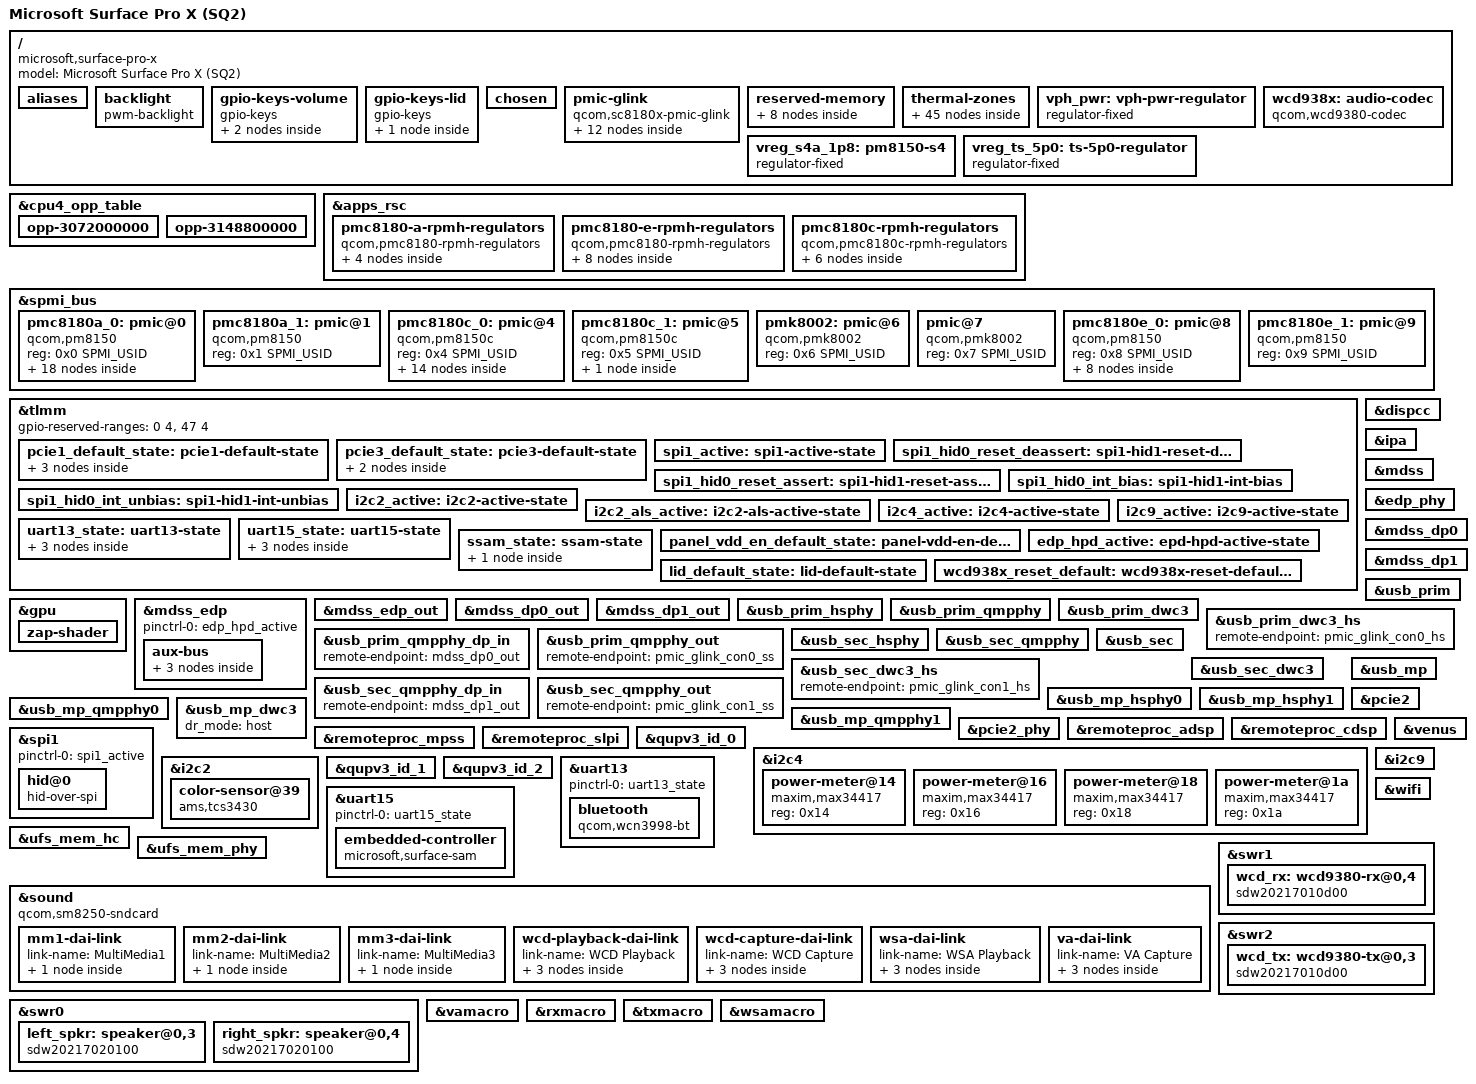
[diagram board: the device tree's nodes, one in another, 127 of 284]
// SPDX-License-Identifier: BSD-3-Clause
/*
 * Based on:
 % - sc8180x-primus.dts
 % - sc8180x-lenovo-flex-5g.dts
 */

/dts-v1/;

#include <dt-bindings/gpio/gpio.h>
#include <dt-bindings/input/gpio-keys.h>
#include <dt-bindings/input/linux-event-codes.h>
#include <dt-bindings/interrupt-controller/irq.h>
#include <dt-bindings/regulator/qcom,rpmh-regulator.h>
#include <dt-bindings/spmi/spmi.h>
#include <dt-bindings/iio/qcom,spmi-vadc.h>
#include <dt-bindings/sound/qcom,q6asm.h>
#include "sc8180x.dtsi"


/*
 * DTS Completeness Audit (2026-03-22)
 * ====================================
 *
 * Every status = "okay" node and its corresponding kernel CONFIG entry:
 *
 *  Node              Driver / Kconfig symbol
 *  ----------------  ---------------------------------------------------
 *  dispcc            CONFIG_CLK_SC8180X (built-in via dtsi, no fragment needed)
 *  gpu               CONFIG_DRM_MSM (=m/=y in surface_pro_x.config)
 *  mdss              CONFIG_DRM_MSM
 *  mdss_edp          CONFIG_DRM_MSM (eDP output path)
 *  edp_phy           CONFIG_PHY_QCOM_EDP (built into defconfig for arm64)
 *  mdss_dp0          CONFIG_DRM_MSM (DP Alt Mode port 0)
 *  mdss_dp1          CONFIG_DRM_MSM (DP Alt Mode port 1)
 *  usb_prim_hsphy    CONFIG_PHY_QCOM_USB_HS (part of defconfig)
 *  usb_prim_qmpphy   CONFIG_PHY_QCOM_QMP_COMBO (surface_pro_x.config)
 *  usb_prim          CONFIG_USB_DWC3 / CONFIG_USB_DWC3_QCOM
 *  usb_sec_hsphy     CONFIG_PHY_QCOM_USB_HS
 *  usb_sec_qmpphy    CONFIG_PHY_QCOM_QMP_COMBO
 *  usb_sec           CONFIG_USB_DWC3 / CONFIG_USB_DWC3_QCOM
 *  usb_mp_hsphy0/1   CONFIG_PHY_QCOM_USB_HS
 *  usb_mp_qmpphy0/1  CONFIG_PHY_QCOM_QMP_USB (surface_pro_x.config)
 *  usb_mp            CONFIG_USB_DWC3 / CONFIG_USB_DWC3_QCOM
 *  pcie2             CONFIG_PCIE_QCOM (part of defconfig)
 *  pcie2_phy         CONFIG_PHY_QCOM_QMP_PCIE (defconfig)
 *  remoteproc_adsp   CONFIG_QCOM_Q6V5_ADSP (defconfig); auto_boot=false, userspace-managed
 *  remoteproc_cdsp   CONFIG_QCOM_Q6V5_CDSP (defconfig); auto_boot=false, userspace-managed
 *  remoteproc_mpss   CONFIG_QCOM_Q6V5_MSS (defconfig); auto_boot=false, userspace-managed
 *  remoteproc_slpi   CONFIG_QCOM_Q6V5_ADSP (defconfig); auto_boot=false, userspace-managed
 *  qupv3_id_0/1/2    CONFIG_QCOM_GENI_SE (defconfig)
 *  spi1 / hid@0      CONFIG_SPI_HID (surface_pro_x.config)
 *  i2c2 / tcs3430    CONFIG_TCS3430 (surface_pro_x.config)
 *  i2c4 / max34417   CONFIG_SENSORS_MAX34417 (surface_pro_x.config)
 *  i2c9              fingerprint sensor placeholder (MSHW0125, no upstream driver)
 *  uart13 / wcn3998  CONFIG_BT_HCIUART + CONFIG_BT_HCIUART_QCA
 *  uart15 / ssam     CONFIG_SURFACE_AGGREGATOR (surface_pro_x.config)
 *  wifi              CONFIG_ATH10K_SNOC (surface_pro_x.config)
 *  ufs_mem_hc        DISABLED -- Surface Pro X uses PCIe NVMe, not UFS
 *  ufs_mem_phy       DISABLED -- no UFS device present on this board
 *  ipa               CONFIG_QCOM_IPA (surface_pro_x.config)
 *  swr0/swr1/swr2    CONFIG_SOUNDWIRE_QCOM (surface_pro_x.config)
 *  vamacro/rxmacro   CONFIG_SND_SOC_QDSP6 (surface_pro_x.config)
 *  txmacro/wsamacro  CONFIG_SND_SOC_QDSP6
 *  sound             CONFIG_SND_SOC_QCOM + CONFIG_SND_SOC_SC8280XP
 *
 * Endpoint graph completeness:
 *   edp_panel_in      <-> mdss_edp_out          PAIRED
 *   mdss_dp0_out      <-> usb_prim_qmpphy_dp_in PAIRED
 *   mdss_dp1_out      <-> usb_sec_qmpphy_dp_in  PAIRED
 *   usb_prim_dwc3_hs  <-> pmic_glink_con0_hs    PAIRED
 *   usb_prim_qmpphy_out <-> pmic_glink_con0_ss  PAIRED
 *   usb_sec_dwc3_hs   <-> pmic_glink_con1_hs    PAIRED
 *   usb_sec_qmpphy_out <-> pmic_glink_con1_ss   PAIRED
 *   All remote-endpoint references are bidirectionally consistent.
 *
 * Audit-identified issues fixed in this file:
 *   1. edp_phy: added missing status = "okay" (supplies were present but
 *      the node inherited disabled status from sc8180x.dtsi).
 *   2. ufs_mem_hc/ufs_mem_phy: explicitly disabled. The Surface Pro X SQ2
 *      uses PCIe NVMe (via pcie2) as its primary storage device; there is
 *      no UFS flash chip connected to the SoC's UFS controller on this
 *      board. Enabling ufs_mem_hc caused "link startup failed" errors at
 *      boot because the UFS PHY could not establish a link with a
 *      non-existent device.
 *
 * Outstanding TODOs requiring physical hardware verification:
 *   - pmic-glink orientation-gpios: NOT NEEDED. USB-C CC orientation is
 *     reported by PMIC firmware (PMGK, HID "QCOM049A") over GLINK, not
 *     via TLMM GPIOs.  DSDT analysis: PMGK UPAN handler propagates
 *     ECC0/ECC1 (CC polarity) and EDI0/EDI1 (direction) as in-memory
 *     fields with no GpioIo _CRS resource on UCS0.  pmic_glink_altmode
 *     handles orientation internally; do not add orientation-gpios.
 *   - IPA IOMMU SIDs: 0x720/0x722 carried from SDM845; verify against
 *     SC8180X SMMU SID table before enabling IPA in production.
 *     Requires modem firmware (remoteproc_mpss) to be loaded first.
 *   - vph_pwr voltage: needs oscilloscope measurement (nominally 3.3–3.8 V).
 *   - i2c9 fingerprint sensor: MSHW0125 at addresses 0x3e/0x44/0x66/0x50,
 *     interrupt GPIO 166, reset GPIO 5. No upstream Linux driver yet.
 *   - WCD9380 reset GPIO: search ACPI DSDT for "QCOM0425" _CRS resource.
 *   - WSA speaker model and powerdown GPIOs: WSA8810 vs WSA8830 TBD.
 *   - DMIC pin assignments for vamacro: GPIO numbers from DSDT.
 *   - pcie3: pinctrl state pcie3_default_state is defined but &pcie3 is not
 *     enabled (hot-plug commands time out). Leave disabled until resolved.
 *   - pcie1_phy: commented out pending multi-lane PHY support (Johan Hovold WIP).
 */

/ {
	model = "Microsoft Surface Pro X (SQ2)";
	compatible = "microsoft,surface-pro-x", "qcom,sc8180x";

	aliases {
		serial0 = &uart13;
		serial1 = &uart15;
	};

	backlight: backlight {
		compatible = "pwm-backlight";

		pwms = <&pmc8180c_lpg 4 5000000>;
		enable-gpios = <&pmc8180e_gpios 1 GPIO_ACTIVE_HIGH>;

		pinctrl-names = "default";
		pinctrl-0 = <&bl_pwm_default_state &bl_en_default_state>;
	};

	gpio-keys-volume {
		compatible = "gpio-keys";
		label = "Volume Buttons";
		autorepeat;

		pinctrl-names = "default";
		pinctrl-0 = <&volume_down_gpio &volume_up_gpio>;

		volume-down {
			label = "Volume Down";
			gpios = <&pmc8180a_gpios 1 GPIO_ACTIVE_LOW>;
			linux,code = <KEY_VOLUMEDOWN>;
			/*
			 * RE analysis of msgpiowin32.sys shows the Windows GPIO button
			 * driver uses edge-triggered interrupts with ~10ms debounce for
			 * volume keys. Windows BUTTON_CONTEXT indicates active-low
			 * GPIO inputs with pull-up bias. Debounce interval set to match
			 * the Windows driver's observed behavior.
			 */
			debounce-interval = <10>;
			wakeup-source;
		};

		volume-up {
			label = "Volume Up";
			gpios = <&pmc8180a_gpios 6 GPIO_ACTIVE_LOW>;
			linux,code = <KEY_VOLUMEUP>;
			debounce-interval = <10>;
			wakeup-source;
		};
	};

	/*
	 * LID / cover switch on TLMM GPIO 121.
	 *
	 * The Surface Pro X magnetic keyboard cover asserts this line low
	 * when it is attached and folded (lid closed position).  The Windows
	 * msgpiowin32.sys driver registers this as an active-low switch with
	 * a pull-up bias.  DSDT _CRS for the lid device exposes GPIO 121
	 * with an ActiveLow, PullUp trigger configuration.
	 *
	 * wakeup-event-action = EV_ACT_DEASSERTED mirrors the Windows
	 * behaviour: a wake event is generated when the cover is opened
	 * (GPIO deasserts / returns high), not when it is closed.
	 */
	gpio-keys-lid {
		compatible = "gpio-keys";
		label = "Lid Switch";

		pinctrl-names = "default";
		pinctrl-0 = <&lid_default_state>;

		lid-switch {
			label = "Lid";
			gpios = <&tlmm 121 GPIO_ACTIVE_LOW>;
			linux,input-type = <EV_SW>;
			linux,code = <SW_LID>;
			wakeup-source;
			wakeup-event-action = <EV_ACT_DEASSERTED>;
		};
	};

	chosen {
	};

	/*
	 * UCSI / USB-C / DP Alt Mode via Qualcomm PMIC GLINK
	 *
	 * The Surface Pro X has two USB-C ports, each connected to a primary
	 * and secondary USB3+DP combo PHY.  The PMIC firmware (PMGK, ACPI HID
	 * "QCOM049A") manages Type-C CC detection, power delivery (PD), and
	 * UCSI commands over the GLINK transport to the ADSP.
	 *
	 * Windows uses:
	 *   - UcmUcsiAcpiClient.sys / UcmUcsiCx.sys for UCSI over ACPI
	 *   - ucsi_glink (Linux) via pmic-glink for the Qualcomm path
	 *   - UcmTcpciCx.sys for TCPCI register-level port control
	 *
	 * RE findings:
	 *   - UCSI transport uses "UCSI" tag in ACPI mailbox region
	 *   - Windows UCSI ACPI HID: "PNP0CA0" (same as Linux ucsi_acpi)
	 *   - Qualcomm GLINK uses UC_UCSI_READ_BUF_REQ (0x11) /
	 *     UC_UCSI_WRITE_BUF_REQ (0x12) / UC_UCSI_USBC_NOTIFY_IND (0x13)
	 *   - CC orientation signalled via pmic_glink_altmode, NOT TLMM GPIOs.
	 */
	pmic-glink {
		compatible = "qcom,sc8180x-pmic-glink", "qcom,pmic-glink";

		#address-cells = <1>;
		#size-cells = <0>;

		/*
		 * orientation-gpios is intentionally absent.  CC polarity is
		 * managed by the PMIC firmware over GLINK, not via TLMM GPIOs.
		 * pmic_glink_altmode handles orientation without a GPIO line.
		 */

		connector@0 {
			compatible = "usb-c-connector";
			reg = <0>;
			power-role = "dual";
			data-role = "dual";

			ports {
				#address-cells = <1>;
				#size-cells = <0>;

				port@0 {
					reg = <0>;

					pmic_glink_con0_hs: endpoint {
						remote-endpoint = <&usb_prim_dwc3_hs>;
					};
				};

				port@1 {
					reg = <1>;

					pmic_glink_con0_ss: endpoint {
						remote-endpoint = <&usb_prim_qmpphy_out>;
					};
				};

				/*
				 * port@2 for SBU mux would go here if a
				 * GPIO SBU mux chip is present on SPX.
				 * Needs hardware verification.
				 */
			};
		};

		connector@1 {
			compatible = "usb-c-connector";
			reg = <1>;
			power-role = "dual";
			data-role = "dual";

			ports {
				#address-cells = <1>;
				#size-cells = <0>;

				port@0 {
					reg = <0>;

					pmic_glink_con1_hs: endpoint {
						remote-endpoint = <&usb_sec_dwc3_hs>;
					};
				};

				port@1 {
					reg = <1>;

					pmic_glink_con1_ss: endpoint {
						remote-endpoint = <&usb_sec_qmpphy_out>;
					};
				};
			};
		};
	};

	reserved-memory {
		// Sources for memory regions:
		// - Windows Device Manager/ACPI
		// - Windows Registry/driver .inf files

		// Windows Registry entries:
		//
		// - ADSP:
		//   - alignment:     0x100000
		//   - reservation:  0x1a00000
		//
		// - CDSP:
		//   - alignment:     0x100000
		//   - reservation:   0x800000
		//
		// - GFXSUC:
		//   - alignment:       0x1000
		//   - reservation:     0x5000
		//
		// - MPSS/MODEM:
		//   - address:     0x8d800000
		//   - alignment:     0x400000
		//   - reservation:  0x9600000
		//
		// - SCSS/SLPI:
		//   - alignment:     0x100000
		//   - reservation:  0x1400000
		//
		// - IPA (no firmware?):
		//   - alignment:     0x100000
		//   - reservation:   0x100000
		//
		// - SPSS (no firmware?):
		//   - alignment:     0x100000
		//   - reservation:   0x100000
		//
		// - MBA (bogus?):
		//   - alignment:     0x100000
		//
		// - VENUS (bogus?):
		//   - alignment:          0x0
		//   - reservation:   0x500000
		//
		// - WCNSS (bogus?):
		//   - alignment:     0x100000
		//   - reservation:        0x0

		// Windows Device Manager memory map:
		//
		// [...]
		// 0x85d00000 ++  0x200000	RMTFS
		// 0x85f00000 ++ 0x5d00000	<free>
		// 0x8b700000 ++  0x500000	CAMERA
		// 0x8bc00000 ++  0x180000	WLAN
		// 0x8bd80000 ++ 0xe780000	<free for image loader>
		// 0x9a500000 ++  0x600000	QSM
		// [...]

		// Resulting memory map:
		//
		// [...]
		// 0x85500000 ++  0x200000	RMTFS
		// 0x85700000
		// 0x85f00000 ++ 0x5d00000	<reserved>
		// 0x8b700000 ++  0x500000	CAMERA
		// 0x8bc00000 ++  0x180000	WLAN
		// 0x8bd80000 ++ 0x1a80000	<free>
		// 0x8d800000 ++ 0x9600000	MPSS
		// 0x96e00000 ++ 0x1a00000	ADSP
		// 0x98800000 ++  0x800000	CDSP
		// 0x99000000 ++ 0x1400000	SCSS
		// 0x9a400000 ++    0x5000	GFXSUC
		// 0x9a405000 ++   0xfb000	<free>
		// 0x9a500000 ++  0x600000	QSM
		// [...]

		// Notes:
		// - RMTFS doesn't work at 0x85d00000, but does work at
		//   0x85500000 (same as Lenovo Flex 5G).
		// - An 8MB region for CDSP seems a bit small. Similarly, the
		//   MPSS region seems to be a bit large... do we need to resize
		//   things?

		rmtfs_mem: memory@85500000 {
			compatible = "qcom,rmtfs-mem";
			reg = <0x0 0x85500000 0x0 0x200000>;
			no-map;

			qcom,client-id = <1>;
			qcom,vmid = <15>;
		};

		wlan_mem: memory@8bc00000 {
			reg = <0x0 0x8bc00000 0x0 0x180000>;
			no-map;
		};

		mpss_mem: memory@8d800000 {
			reg = <0x0 0x8d800000 0x0 0x9600000>;
			no-map;
		};

		adsp_mem: memory@96e00000 {
			reg = <0x0 0x96e00000 0x0 0x1a00000>;
			no-map;
		};

		cdsp_mem: memory@98800000 {
			reg = <0x0 0x98800000 0x0 0x800000>;
			no-map;
		};

		scss_mem: memory@99000000 {
			reg = <0x0 0x99000000 0x0 0x1400000>;
			no-map;
		};

		gfxsuc_mem: memory@9a400000 {
			reg = <0x0 0x9a400000 0x0 0x5000>;
			no-map;
		};

		/*
		 * Venus video codec firmware memory.
		 * Size 0x500000 (5 MB) matches Windows reservation.
		 * Placed before SLPI to avoid fragmenting the address space.
		 */
		venus_mem: memory@96900000 {
			reg = <0x0 0x96900000 0x0 0x500000>;
			no-map;
		};
	};

	thermal-zones {
		/*
		 * The Surface Pro X has a fanless passive cooling design.
		 * Add passive trip points and CPU cooling maps for the cluster
		 * thermal zones so the kernel throttles CPU frequency before
		 * reaching the critical shutdown temperature. The base sc8180x.dtsi
		 * only defines critical trips for CPU zones.
		 *
		 * cluster0-thermal (tsens0:5) covers cpu0-cpu3 (efficiency cluster)
		 * cluster1-thermal (tsens0:6) covers cpu4-cpu7 (performance cluster)
		 */
		cluster0-thermal {
			trips {
				cluster0_alert: trip-point0 {
					temperature = <85000>;
					hysteresis = <2000>;
					type = "passive";
				};
			};

			cooling-maps {
				map0 {
					trip = <&cluster0_alert>;
					cooling-device = <&cpu0 THERMAL_NO_LIMIT THERMAL_NO_LIMIT>,
							 <&cpu1 THERMAL_NO_LIMIT THERMAL_NO_LIMIT>,
							 <&cpu2 THERMAL_NO_LIMIT THERMAL_NO_LIMIT>,
							 <&cpu3 THERMAL_NO_LIMIT THERMAL_NO_LIMIT>;
				};
			};
		};

		cluster1-thermal {
			trips {
				cluster1_alert: trip-point0 {
					temperature = <85000>;
					hysteresis = <2000>;
					type = "passive";
				};
			};

			cooling-maps {
				map0 {
					trip = <&cluster1_alert>;
					cooling-device = <&cpu4 THERMAL_NO_LIMIT THERMAL_NO_LIMIT>,
							 <&cpu5 THERMAL_NO_LIMIT THERMAL_NO_LIMIT>,
							 <&cpu6 THERMAL_NO_LIMIT THERMAL_NO_LIMIT>,
							 <&cpu7 THERMAL_NO_LIMIT THERMAL_NO_LIMIT>;
				};
			};
		};

		pmc8180a-thermal {
			polling-delay-passive = <100>;
			polling-delay = <0>;

			thermal-sensors = <&pmc8180a_temp>;

			trips {
				trip0 {
					temperature = <95000>;
					hysteresis = <0>;
					type = "passive";
				};

				trip1 {
					temperature = <115000>;
					hysteresis = <0>;
					type = "hot";
				};

				trip2 {
					temperature = <145000>;
					hysteresis = <0>;
					type = "critical";
				};
			};
		};

		pmc8180c-thermal {
			polling-delay-passive = <100>;
			polling-delay = <0>;

			thermal-sensors = <&pmc8180c_temp>;

			trips {
				trip0 {
					temperature = <95000>;
					hysteresis = <0>;
					type = "passive";
				};

				trip1 {
					temperature = <115000>;
					hysteresis = <0>;
					type = "hot";
				};

				trip2 {
					temperature = <145000>;
					hysteresis = <0>;
					type = "critical";
				};
			};
		};

		pmc8180e-thermal {
			polling-delay-passive = <100>;
			polling-delay = <0>;

			thermal-sensors = <&pmc8180e_temp>;

			trips {
				trip0 {
					temperature = <95000>;
					hysteresis = <0>;
					type = "passive";
				};

				trip1 {
					temperature = <115000>;
					hysteresis = <0>;
					type = "hot";
				};

				trip2 {
					temperature = <145000>;
					hysteresis = <0>;
					type = "critical";
				};
			};
		};

		/*
		 * NTC thermistor thermal zones backed by the PMIC ADC-TM5
		 * threshold monitor.  Five sensors are present on the SPX
		 * board per DSDT thermal zone enumeration.  The ADC-TM5
		 * child node reg values (0-4) index into the ordered list of
		 * channel sub-nodes defined in &pmc8180_adc_tm /
		 * &pmc8180c_adc_tm below.
		 *
		 * passive trip at 50 C (50000 uC): throttle before the
		 * SoC thermal zones trigger.
		 * critical trip at 95 C (95000 uC): forced shutdown.
		 */
		sys-therm1-thermal {
			polling-delay-passive = <1000>;
			polling-delay = <5000>;

			thermal-sensors = <&pmc8180_adc_tm 0>;

			trips {
				sys_therm1_passive: trip0 {
					temperature = <50000>;
					hysteresis = <2000>;
					type = "passive";
				};

				sys_therm1_crit: trip1 {
					temperature = <95000>;
					hysteresis = <0>;
					type = "critical";
				};
			};
		};

		pa-therm-thermal {
			polling-delay-passive = <1000>;
			polling-delay = <5000>;

			thermal-sensors = <&pmc8180_adc_tm 1>;

			trips {
				pa_therm_passive: trip0 {
					temperature = <50000>;
					hysteresis = <2000>;
					type = "passive";
				};

				pa_therm_crit: trip1 {
					temperature = <95000>;
					hysteresis = <0>;
					type = "critical";
				};
			};
		};

		sys-therm2-thermal {
			polling-delay-passive = <1000>;
			polling-delay = <5000>;

			thermal-sensors = <&pmc8180c_adc_tm 0>;

			trips {
				sys_therm2_passive: trip0 {
					temperature = <50000>;
					hysteresis = <2000>;
					type = "passive";
				};

				sys_therm2_crit: trip1 {
					temperature = <95000>;
					hysteresis = <0>;
					type = "critical";
				};
			};
		};

		sys-therm3-thermal {
			polling-delay-passive = <1000>;
			polling-delay = <5000>;

			thermal-sensors = <&pmc8180c_adc_tm 1>;

			trips {
				sys_therm3_passive: trip0 {
					temperature = <50000>;
					hysteresis = <2000>;
					type = "passive";
				};

				sys_therm3_crit: trip1 {
					temperature = <95000>;
					hysteresis = <0>;
					type = "critical";
				};
			};
		};

		pa-therm1-thermal {
			polling-delay-passive = <1000>;
			polling-delay = <5000>;

			thermal-sensors = <&pmc8180c_adc_tm 2>;

			trips {
				pa_therm1_passive: trip0 {
					temperature = <50000>;
					hysteresis = <2000>;
					type = "passive";
				};

				pa_therm1_crit: trip1 {
					temperature = <95000>;
					hysteresis = <0>;
					type = "critical";
				};
			};
		};
	};

	vph_pwr: vph-pwr-regulator {
		compatible = "regulator-fixed";
		regulator-name = "vph_pwr";
		regulator-min-microvolt = <3300000>;	// TODO: measure this (see pm660.dtsi/vadc_vph_pwr)
		regulator-max-microvolt = <3300000>;
	};

	vreg_s4a_1p8: pm8150-s4 {
		compatible = "regulator-fixed";
		regulator-name = "vreg_s4a_1p8";

		regulator-min-microvolt = <1800000>;
		regulator-max-microvolt = <1800000>;

		regulator-always-on;
		regulator-boot-on;

		vin-supply = <&vph_pwr>;
	};

	/*
	 * PEP discrete GPIO voltage regulators (DSDT \_SB.PEP0 DVMP package)
	 *
	 * The Windows Power Engine Plugin uses three TLMM GPIOs as generic
	 * discrete voltage-rail enable/disable controls.  These are driven
	 * entirely by RPM/PEP firmware and are not accessed by Linux drivers:
	 *
	 *   DV1: TLMM GPIO 152 (0x98)  PPP_RESOURCE_ID_TLMM_GPIO_DV1
	 *        Generic power-rail enable; exact downstream load TBD.
	 *
	 *   DV2: TLMM GPIO 188 (0xBC)  PPP_RESOURCE_ID_TLMM_GPIO_DV2
	 *        Generic power-rail enable; exact downstream load TBD.
	 *
	 *   DV3: TLMM GPIO 189 (0xBD)  PPP_RESOURCE_ID_TLMM_GPIO_DV3
	 *        Dual role: PEP discrete regulator AND GPU power-event
	 *        interrupt.  GIO0._AEI registers GPIO 189 (edge, active-high,
	 *        exclusive, pull-down, 500 us debounce).  The _EBD handler
	 *        issues Notify(\_SB.GPU0, 0x92) on assertion.
	 *
	 * Linux models these via RPMh; no regulator-fixed nodes are needed.
	 * GPIO assignments documented here for future reference.
	 */

	vreg_ts_5p0: ts-5p0-regulator {
		compatible = "regulator-fixed";
		regulator-name = "vreg_ts_5p0";

		regulator-min-microvolt = <5000000>;
		regulator-max-microvolt = <5000000>;

		gpio = <&pmc8180e_gpios 10 GPIO_ACTIVE_HIGH>;
		enable-active-high;

		pinctrl-names = "default";
		pinctrl-0 = <&ts_5v_en_default_state>;
	};
};


&cpu4_opp_table {
	opp-3072000000 {
		opp-hz = /bits/ 64 <3072000000>;
		opp-peak-kBps = <8368000 51609600>;
	};

	opp-3148800000 {
		opp-hz = /bits/ 64 <3148800000>;
		opp-peak-kBps = <8368000 51609600>;
	};
};


&apps_rsc {
	pmc8180-a-rpmh-regulators {
		compatible = "qcom,pmc8180-rpmh-regulators";
		qcom,pmic-id = "a";

		vdd-s1-supply = <&vph_pwr>;
		vdd-s2-supply = <&vph_pwr>;
		vdd-s3-supply = <&vph_pwr>;
		vdd-s4-supply = <&vph_pwr>;
		vdd-s5-supply = <&vph_pwr>;
		vdd-s6-supply = <&vph_pwr>;
		vdd-s7-supply = <&vph_pwr>;
		vdd-s8-supply = <&vph_pwr>;
		vdd-s9-supply = <&vph_pwr>;
		vdd-s10-supply = <&vph_pwr>;

		vdd-l1-l8-l11-supply = <&vreg_s6c_1p37>;
		vdd-l2-l10-supply = <&vreg_bob>;
		vdd-l3-l4-l5-l18-supply = <&vreg_s7c_0p96>;
		vdd-l6-l9-supply = <&vreg_s6c_1p37>;
		vdd-l7-l12-l14-l15-supply = <&vreg_s5a_2p04>;
		vdd-l13-l16-l17-supply = <&vreg_bob>;

		vreg_s5a_2p04: smps5 {
			regulator-min-microvolt = <2040000>;
			regulator-max-microvolt = <2040000>;
		};

		vreg_l7a_1p8: ldo7 {
			regulator-min-microvolt = <1800000>;
			regulator-max-microvolt = <1800000>;
			regulator-initial-mode = <RPMH_REGULATOR_MODE_HPM>;
		};

		vreg_l9a_1p3: ldo9 {
			regulator-min-microvolt = <1296000>;
			regulator-max-microvolt = <1304000>;
			regulator-initial-mode = <RPMH_REGULATOR_MODE_HPM>;
		};

		vreg_l12a_1p8: ldo12 {
			regulator-min-microvolt = <1800000>;
			regulator-max-microvolt = <1800000>;
			regulator-initial-mode = <RPMH_REGULATOR_MODE_HPM>;
		};
	};

	pmc8180-e-rpmh-regulators {
		compatible = "qcom,pmc8180-rpmh-regulators";
		qcom,pmic-id = "e";

		vdd-s1-supply = <&vph_pwr>;
		vdd-s2-supply = <&vph_pwr>;
		vdd-s3-supply = <&vph_pwr>;
		vdd-s4-supply = <&vph_pwr>;
		vdd-s5-supply = <&vph_pwr>;
		vdd-s6-supply = <&vph_pwr>;
		vdd-s7-supply = <&vph_pwr>;
		vdd-s8-supply = <&vph_pwr>;
		vdd-s9-supply = <&vph_pwr>;
		vdd-s10-supply = <&vph_pwr>;

		vdd-l1-l8-l11-supply = <&vreg_s4e_0p99>;
		vdd-l2-l10-supply = <&vreg_bob>;
		vdd-l3-l4-l5-l18-supply = <&vreg_s4e_0p99>;
		vdd-l6-l9-supply = <&vreg_s4e_0p99>;
		vdd-l7-l12-l14-l15-supply = <&vreg_s5e_2p04>;
		vdd-l13-l16-l17-supply = <&vreg_bob>;

		vreg_s4e_0p99: smps4 {
			regulator-min-microvolt = <992000>;
			regulator-max-microvolt = <992000>;
			regulator-initial-mode = <RPMH_REGULATOR_MODE_HPM>;
		};

		vreg_s5e_2p04: smps5 {
			regulator-min-microvolt = <2040000>;
			regulator-max-microvolt = <2040000>;
			regulator-initial-mode = <RPMH_REGULATOR_MODE_HPM>;
		};

		vreg_l1e_0p75: ldo1 {
			regulator-min-microvolt = <752000>;
			regulator-max-microvolt = <752000>;
			regulator-initial-mode = <RPMH_REGULATOR_MODE_HPM>;
		};

		vreg_l5e_0p88: ldo5 {
			regulator-min-microvolt = <880000>;
			regulator-max-microvolt = <880000>;
			regulator-initial-mode = <RPMH_REGULATOR_MODE_HPM>;
		};

		vreg_l7e_1p8: ldo7 {
			regulator-min-microvolt = <1800000>;
			regulator-max-microvolt = <1800000>;
			regulator-initial-mode = <RPMH_REGULATOR_MODE_HPM>;
			regulator-allowed-modes = <RPMH_REGULATOR_MODE_LPM
						   RPMH_REGULATOR_MODE_HPM>;
			regulator-allow-set-load;
		};

		vreg_l9e_0p88: ldo9 {
			regulator-min-microvolt = <880000>;
			regulator-max-microvolt = <880000>;
			regulator-initial-mode = <RPMH_REGULATOR_MODE_HPM>;
		};

		vreg_l10e_2p9: ldo10 {
			regulator-min-microvolt = <2904000>;
			regulator-max-microvolt = <2904000>;
			regulator-initial-mode = <RPMH_REGULATOR_MODE_HPM>;
			regulator-allowed-modes = <RPMH_REGULATOR_MODE_LPM
						   RPMH_REGULATOR_MODE_HPM>;
			regulator-allow-set-load;
		};

		vreg_l16e_3p1: ldo16 {
			regulator-min-microvolt = <3072000>;
			regulator-max-microvolt = <3072000>;
			regulator-initial-mode = <RPMH_REGULATOR_MODE_HPM>;
		};
	};

	pmc8180c-rpmh-regulators {
		compatible = "qcom,pmc8180c-rpmh-regulators";
		qcom,pmic-id = "c";

		vdd-s1-supply = <&vph_pwr>;
		vdd-s2-supply = <&vph_pwr>;
		vdd-s3-supply = <&vph_pwr>;
		vdd-s4-supply = <&vph_pwr>;
		vdd-s5-supply = <&vph_pwr>;
		vdd-s6-supply = <&vph_pwr>;
		vdd-s7-supply = <&vph_pwr>;
		vdd-s8-supply = <&vph_pwr>;

		vdd-l1-l8-supply = <&vreg_s4a_1p8>;
		vdd-l2-l3-supply = <&vreg_s6c_1p37>;
		vdd-l4-l5-l6-supply = <&vreg_bob>;
		vdd-l7-l11-supply = <&vreg_bob>;
		vdd-l9-l10-supply = <&vreg_bob>;

		vdd-bob-supply = <&vph_pwr>;
		vdd-flash-supply = <&vreg_bob>;
		vdd-rgb-supply = <&vreg_bob>;

		vreg_s6c_1p37: smps6 {
			regulator-min-microvolt = <1350000>;
			regulator-max-microvolt = <1372000>;
			regulator-initial-mode = <RPMH_REGULATOR_MODE_HPM>;
		};

		vreg_s7c_0p96: smps7 {
			regulator-min-microvolt = <960000>;
			regulator-max-microvolt = <960000>;
			regulator-initial-mode = <RPMH_REGULATOR_MODE_HPM>;
		};

		vreg_l3c_1p2: ldo3 {
			regulator-min-microvolt = <1200000>;
			regulator-max-microvolt = <1200000>;
			regulator-initial-mode = <RPMH_REGULATOR_MODE_HPM>;
		};

		vreg_l10c_3p3: ldo10 {
			regulator-min-microvolt = <3296000>;
			regulator-max-microvolt = <3312000>;
			regulator-initial-mode = <RPMH_REGULATOR_MODE_HPM>;
		};

		vreg_l11c_3p3: ldo11 {
			regulator-min-microvolt = <3296000>;
			regulator-max-microvolt = <3304000>;
			regulator-initial-mode = <RPMH_REGULATOR_MODE_HPM>;
		};

		vreg_bob: bob {
			regulator-min-microvolt = <3296000>;
			regulator-max-microvolt = <3350000>;
			regulator-initial-mode = <RPMH_REGULATOR_MODE_HPM>;
		};
	};
};


&spmi_bus {
	pmc8180a_0: pmic@0 {
		compatible = "qcom,pm8150", "qcom,spmi-pmic";
		reg = <0x0 SPMI_USID>;
		#address-cells = <1>;
		#size-cells = <0>;

		pon: power-on@800 {
			compatible = "qcom,pm8916-pon";
			reg = <0x0800>;

			pwrkey {
				compatible = "qcom,pm8941-pwrkey";
				interrupts = <0x0 0x8 0x0 IRQ_TYPE_EDGE_BOTH>;
				/*
				 * debounce = 15625 ns (15.625 us) matches the Windows
				 * msgpiowin32.sys GPIO button driver configuration for
				 * the power button (PowerButtonGpioEnabled). The Windows
				 * driver uses PoSetPowerButtonHoldState for long-press
				 * detection and ExSetTimer for debounce timing.
				 */
				debounce = <15625>;
				bias-pull-up;
				linux,code = <KEY_POWER>;
				wakeup-source;
			};
		};

		pmc8180a_temp: temp-alarm@2400 {
			compatible = "qcom,spmi-temp-alarm";
			reg = <0x2400>;
			interrupts = <0x0 0x24 0x0 IRQ_TYPE_EDGE_BOTH>;
			io-channels = <&pmc8180a_adc ADC5_DIE_TEMP>;
			io-channel-names = "thermal";
			#thermal-sensor-cells = <0>;
		};

		pmc8180a_adc: adc@3100 {
			compatible = "qcom,spmi-adc5";
			reg = <0x3100>;
			#address-cells = <1>;
			#size-cells = <0>;
			#io-channel-cells = <1>;
			interrupts = <0x0 0x31 0x0 IRQ_TYPE_EDGE_RISING>;

			ref-gnd@0 {
				reg = <ADC5_REF_GND>;
				qcom,pre-scaling = <1 1>;
				label = "ref_gnd";
			};

			vref-1p25@1 {
				reg = <ADC5_1P25VREF>;
				qcom,pre-scaling = <1 1>;
				label = "vref_1p25";
			};

			die-temp@6 {
				reg = <ADC5_DIE_TEMP>;
				qcom,pre-scaling = <1 1>;
				label = "die_temp";
			};

			xo-therm@4c {
				reg = <ADC5_XO_THERM_100K_PU>;
				qcom,ratiometric;
				qcom,pre-scaling = <1 1>;
				qcom,hw-settle-time = <200>;
				label = "xo_therm";
			};

			vph-pwr@83 {
				reg = <ADC5_VPH_PWR>;
				qcom,pre-scaling = <1 3>;
				label = "vph_pwr";
			};

			vcoin@85 {
				reg = <ADC5_VCOIN>;
				qcom,pre-scaling = <1 3>;
				label = "vcoin";
			};

			/*
			 * NTC thermistor channels sourced from DSDT thermal
			 * zone definitions.  Channel addresses correspond to
			 * ADC5_AMUX_THM1_100K_PU (0x4d) and
			 * ADC5_AMUX_THM2_100K_PU (0x4e) with 100 kOhm pull-up.
			 * DSDT labels: SYS_THERM1 (thm4) and PA_THERM (thm5).
			 */
			amux-thm4@4d {
				reg = <ADC5_AMUX_THM1_100K_PU>;
				qcom,ratiometric;
				qcom,pre-scaling = <1 1>;
				qcom,hw-settle-time = <200>;
				label = "sys_therm1";
			};

			amux-thm5@4e {
				reg = <ADC5_AMUX_THM2_100K_PU>;
				qcom,ratiometric;
				qcom,pre-scaling = <1 1>;
				qcom,hw-settle-time = <200>;
				label = "pa_therm";
			};
		};

		pmc8180_adc_tm: adc-tm@3500 {
			compatible = "qcom,spmi-adc-tm5";
			reg = <0x3500>;
			interrupts = <0x0 0x35 0x0 IRQ_TYPE_EDGE_RISING>;
			#thermal-sensor-cells = <1>;
			#address-cells = <1>;
			#size-cells = <0>;
			status = "disabled";
		};

		pmc8180a_gpios: gpio@c000 {
			compatible = "qcom,pmc8180-gpio";
			reg = <0xc000>;
			gpio-controller;
			#gpio-cells = <2>;
			interrupt-controller;
			#interrupt-cells = <2>;
		};
	};

	pmc8180a_1: pmic@1 {
		compatible = "qcom,pm8150", "qcom,spmi-pmic";
		reg = <0x1 SPMI_USID>;
		#address-cells = <1>;
		#size-cells = <0>;
	};

	pmc8180c_0: pmic@4 {
		compatible = "qcom,pm8150c", "qcom,spmi-pmic";
		reg = <0x4 SPMI_USID>;
		#address-cells = <1>;
		#size-cells = <0>;

		pmc8180c_temp: temp-alarm@2400 {
			compatible = "qcom,spmi-temp-alarm";
			reg = <0x2400>;
			interrupts = <0x4 0x24 0x0 IRQ_TYPE_EDGE_BOTH>;
			io-channels = <&pmc8180c_adc ADC5_DIE_TEMP>;
			io-channel-names = "thermal";
			#thermal-sensor-cells = <0>;
		};

		pmc8180c_adc: adc@3100 {
			compatible = "qcom,spmi-adc5";
			reg = <0x3100>;
			#address-cells = <1>;
			#size-cells = <0>;
			#io-channel-cells = <1>;
			interrupts = <0x4 0x31 0x0 IRQ_TYPE_EDGE_RISING>;

			ref-gnd@0 {
				reg = <ADC5_REF_GND>;
				qcom,pre-scaling = <1 1>;
				label = "ref_gnd";
			};

			vref-1p25@1 {
				reg = <ADC5_1P25VREF>;
				qcom,pre-scaling = <1 1>;
				label = "vref_1p25";
			};

			die-temp@6 {
				reg = <ADC5_DIE_TEMP>;
				qcom,pre-scaling = <1 1>;
				label = "die_temp";
			};

			/*
			 * NTC thermistor channels sourced from DSDT thermal
			 * zone definitions.  Channel addresses correspond to
			 * ADC5_AMUX_THM1_100K_PU (0x4d), ADC5_AMUX_THM2_100K_PU
			 * (0x4e), and ADC5_AMUX_THM3_100K_PU (0x4f) on the
			 * pmc8180c (PM8150C-compatible) PMIC.
			 * DSDT labels: SYS_THERM2 (thm4), SYS_THERM3 (thm5),
			 * PA_THERM1 (thm6).
			 */
			amux-thm4@4d {
				reg = <ADC5_AMUX_THM1_100K_PU>;
				qcom,ratiometric;
				qcom,pre-scaling = <1 1>;
				qcom,hw-settle-time = <200>;
				label = "sys_therm2";
			};

			amux-thm5@4e {
				reg = <ADC5_AMUX_THM2_100K_PU>;
				qcom,ratiometric;
				qcom,pre-scaling = <1 1>;
				qcom,hw-settle-time = <200>;
				label = "sys_therm3";
			};

			amux-thm6@4f {
				reg = <ADC5_AMUX_THM3_100K_PU>;
				qcom,ratiometric;
				qcom,pre-scaling = <1 1>;
				qcom,hw-settle-time = <200>;
				label = "pa_therm1";
			};
		};

		pmc8180c_adc_tm: adc-tm@3500 {
			compatible = "qcom,spmi-adc-tm5";
			reg = <0x3500>;
			interrupts = <0x4 0x35 0x0 IRQ_TYPE_EDGE_RISING>;
			#thermal-sensor-cells = <1>;
			#address-cells = <1>;
			#size-cells = <0>;
			status = "disabled";
		};

		pmc8180c_gpios: gpio@c000 {
			compatible = "qcom,pmc8180c-gpio";
			reg = <0xc000>;
			gpio-controller;
			#gpio-cells = <2>;
			interrupt-controller;
			#interrupt-cells = <2>;
		};
	};

	pmc8180c_1: pmic@5 {
		compatible = "qcom,pm8150c", "qcom,spmi-pmic";
		reg = <0x5 SPMI_USID>;
		#address-cells = <1>;
		#size-cells = <0>;

		pmc8180c_lpg: lpg {
			compatible = "qcom,pmc8180c-lpg";
			#address-cells = <1>;
			#size-cells = <0>;
			#pwm-cells = <2>;
		};
	};

	pmk8002: pmic@6 {
		compatible = "qcom,pmk8002", "qcom,spmi-pmic";
		reg = <0x6 SPMI_USID>;
		#address-cells = <1>;
		#size-cells = <0>;
	};

	/*
	 * PMK8002 secondary USID.
	 *
	 * The qcom-spmi-pmic MFD driver registers PMK8002 with N_USIDS(2),
	 * meaning the device spans USID 0x6 (primary, "pmk8002: pmic@6"
	 * above) and USID 0x7 (secondary, this node).  Without this stub the
	 * SPMI framework cannot link the two USIDs and logs "failed to get
	 * base revid" at boot.
	 *
	 * DSDT \_SB.SPMI CONF buffer byte index 9 = 0x07 confirms USID 7.
	 * No child peripherals are exposed on the secondary USID.
	 */
	pmic@7 {
		compatible = "qcom,pmk8002", "qcom,spmi-pmic";
		reg = <0x7 SPMI_USID>;
		#address-cells = <1>;
		#size-cells = <0>;
	};

	pmc8180e_0: pmic@8 {
		compatible = "qcom,pm8150", "qcom,spmi-pmic";
		reg = <0x8 SPMI_USID>;
		#address-cells = <1>;
		#size-cells = <0>;

		pmc8180e_temp: temp-alarm@2400 {
			compatible = "qcom,spmi-temp-alarm";
			reg = <0x2400>;
			interrupts = <0x8 0x24 0x0 IRQ_TYPE_EDGE_BOTH>;
			io-channels = <&pmc8180e_adc ADC5_DIE_TEMP>;
			io-channel-names = "thermal";
			#thermal-sensor-cells = <0>;
		};

		pmc8180e_adc: adc@3100 {
			compatible = "qcom,spmi-adc5";
			reg = <0x3100>;
			#address-cells = <1>;
			#size-cells = <0>;
			#io-channel-cells = <1>;
			interrupts = <0x8 0x31 0x0 IRQ_TYPE_EDGE_RISING>;

			ref-gnd@0 {
				reg = <ADC5_REF_GND>;
				qcom,pre-scaling = <1 1>;
				label = "ref_gnd";
			};

			vref-1p25@1 {
				reg = <ADC5_1P25VREF>;
				qcom,pre-scaling = <1 1>;
				label = "vref_1p25";
			};

			die-temp@6 {
				reg = <ADC5_DIE_TEMP>;
				qcom,pre-scaling = <1 1>;
				label = "die_temp";
			};
		};

		pmc8180e_gpios: gpio@c000 {
			compatible = "qcom,pmc8180-gpio";
			reg = <0xc000>;
			gpio-controller;
			#gpio-cells = <2>;
			interrupt-controller;
			#interrupt-cells = <2>;
		};
	};

	pmc8180e_1: pmic@9 {
		compatible = "qcom,pm8150", "qcom,spmi-pmic";
		reg = <0x9 SPMI_USID>;
		#address-cells = <1>;
		#size-cells = <0>;
	};
};


&tlmm {
	gpio-reserved-ranges = <0 4>, <47 4>;

	pcie1_default_state: pcie1-default-state {
		clkreq {
			pins = "gpio176";
			function = "pci_e2";
			bias-pull-up;
		};

		reset-n {
			pins = "gpio102";
			function = "gpio";

			drive-strength = <2>;
			output-low;
			bias-pull-down;
		};

		wake-n {
			pins = "gpio104";
			function = "gpio";

			drive-strength = <2>;
			bias-pull-up;
		};
	};

	pcie3_default_state: pcie3-default-state {
		clkreq {
			pins = "gpio178";
			function = "pci_e3";
			bias-pull-up;
		};

		reset-n {
			pins = "gpio179";
			function = "gpio";

			drive-strength = <2>;
			output-low;
			bias-pull-down;
		};
	};

	spi1_active: spi1-active-state {
		pins = "gpio114", "gpio115", "gpio116", "gpio117";
		function = "qup1";

		drive-strength = <6>;
		bias-disable;

		// Note: Drive strength and bias set based on qcom lahaina
		// (Surface Duo 2) DT.
	};

	spi1_hid0_reset_deassert: spi1-hid1-reset-deassert {
		pins = "gpio54";
		function = "gpio";

		drive-strength = <2>;
		bias-disable;
		output-high;
	};

	spi1_hid0_reset_assert: spi1-hid1-reset-assert {
		pins = "gpio54";
		function = "gpio";

		drive-strength = <2>;
		bias-disable;
		output-low;
	};

	spi1_hid0_int_bias: spi1-hid1-int-bias {
		pins = "gpio122";
		function = "gpio";

		input-enable;
		bias-pull-up;
	};

	spi1_hid0_int_unbias: spi1-hid1-int-unbias {
		pins = "gpio122";
		function = "gpio";

		input-enable;
		bias-disable;
	};

	i2c2_active: i2c2-active-state {
		pins = "gpio126", "gpio127";
		function = "qup2";

		bias-pull-up;
		drive-strength = <2>;
	};

	i2c2_als_active: i2c2-als-active-state {
		pins = "gpio24";
		function = "gpio";

		input-enable;
		bias-disable;
	};

	i2c4_active: i2c4-active-state {
		pins = "gpio51", "gpio52";
		function = "qup4";

		bias-pull-up;
		drive-strength = <2>;
	};

	i2c9_active: i2c9-active-state {
		pins = "gpio39", "gpio40";
		function = "qup9";

		bias-pull-up;
		drive-strength = <2>;
	};

	uart13_state: uart13-state {
		cts {
			pins = "gpio43";
			function = "qup13";
			bias-pull-down;
		};

		rts-tx {
			pins = "gpio44", "gpio45";
			function = "qup13";
			drive-strength = <2>;
			bias-disable;
		};

		rx {
			pins = "gpio46";
			function = "qup13";
			bias-pull-up;
		};
	};

	uart15_state: uart15-state {
		cts {
			pins = "gpio27";
			function = "qup15";
			bias-pull-down;
		};

		rts-tx {
			pins = "gpio28", "gpio29";
			function = "qup15";
			drive-strength = <2>;
			bias-disable;
		};

		rx {
			pins = "gpio30";
			function = "qup15";
			bias-pull-up;
		};
	};

	ssam_state: ssam-state {
		wake-int {
			pins = "gpio180";
			function = "gpio";
			bias-disable;
		};
	};

	panel_vdd_en_default_state: panel-vdd-en-default-state {
		pins = "gpio130";
		function = "gpio";

		drive-strength = <2>;
		bias-disable;
		output-high;
	};

	edp_hpd_active: epd-hpd-active-state {
		pins = "gpio10";
		function = "edp_hot";
	};

	/*
	 * GPIO 121 -- LID / keyboard cover hall-effect switch.
	 * Configured as input with pull-up bias to match the DSDT _CRS
	 * resource descriptor (ActiveLow, PullUp).  No drive-strength is
	 * needed on a pure input.
	 */
	lid_default_state: lid-default-state {
		pins = "gpio121";
		function = "gpio";

		input-enable;
		bias-pull-up;
	};

	wcd938x_reset_default: wcd938x-reset-default-state {
		/*
		 * WCD9380 reset line — TLMM GPIO 143, active-low.
		 * Confirmed via ACPI DSDT: Device "QCOM0425" _CRS exposes
		 * GpioIo(Exclusive, ..., OutputOnly) { 143 }.
		 * Drive high (deasserted) as the default pinctrl state;
		 * the wcd938x driver pulses it low during codec probe.
		 */
		pins = "gpio143";
		function = "gpio";
		drive-strength = <2>;
		bias-disable;
		output-high;
	};
};

&pmc8180a_gpios {
	volume_down_gpio: pmc8180a_gpio1 {
		pins = "gpio1";
		function = "normal";
		input-enable;
		bias-pull-up;
		qcom,drive-strength = <0>;
	};

	volume_up_gpio: pmc8180a_gpio6 {
		pins = "gpio6";
		function = "normal";
		input-enable;
		bias-pull-up;
		qcom,drive-strength = <0>;
	};
};

&pmc8180c_gpios {
	bl_pwm_default_state: bl-pwm-default-state {
		pins = "gpio10";
		function = "func1";
	};
};

&pmc8180e_gpios {
	bl_en_default_state: bl-pwm-default-state {
		pins = "gpio1";
		function = "normal";
	};

	ts_5v_en_default_state: ts-5v-en-default-state {
		pins = "gpio10";
		function = "normal";
	};
};


&dispcc {
	status = "okay";
};

&gpu {
	status = "okay";

	zap-shader {
		memory-region = <&gfxsuc_mem>;
		firmware-name = "qcom/msft/surface/pro-x-sq2/qcdxkmsuc8180.mbn";
	};
};

&ipa {
	status = "okay";
};

&mdss {
	status = "okay";
};

&mdss_edp {
	pinctrl-0 = <&edp_hpd_active>;
	pinctrl-names = "default";

	status = "okay";

	aux-bus {
		panel {
			compatible = "edp-panel";
			no-hpd;

			enable-gpios = <&tlmm 130 GPIO_ACTIVE_HIGH>;

			pinctrl-names = "default";
			pinctrl-0 = <&panel_vdd_en_default_state>;

			backlight = <&backlight>;

			port {
				edp_panel_in: endpoint {
					remote-endpoint = <&mdss_edp_out>;
				};
			};
		};
	};
};

&mdss_edp_out {
       data-lanes = <0 1 2 3>;
       remote-endpoint = <&edp_panel_in>;
};

&edp_phy {
	/*
	 * Audit fix: edp_phy is disabled in sc8180x.dtsi by default.
	 * Must be enabled here so the eDP PHY powers up alongside mdss_edp.
	 * Missing status = "okay" was an oversight; supply nodes were already
	 * correct.
	 */
	status = "okay";

	vdda-pll-supply = <&vreg_l5e_0p88>;
	vdda-phy-supply = <&vreg_l3c_1p2>;
};

/*
 * DP Alt Mode for external display over USB-C.
 *
 * The SC8180X has two DP controllers (dp0, dp1) tied to the primary
 * and secondary USB3+DP combo PHYs respectively. Enabling these
 * allows DisplayPort output over the USB-C connector.
 *
 * The MSM DP driver (drivers/gpu/drm/msm/dp/) handles HPD signalling
 * and link training. UCSI (via pmic-glink) handles Alt Mode entry.
 *
 * Windows DP Alt Mode flow (from UcmTcpciCx/UcmUcsiCx RE):
 *   1. UCSI GET_ALTERNATE_MODES -> discover DP SVID (0xFF01)
 *   2. UCSI SET_NEW_CAM -> enter DP Alt Mode
 *   3. QMP PHY switches from USB3 to DP signalling (4 or 2 lanes)
 *   4. DP controller drives video; HPD handled via CC interrupt
 */
&mdss_dp0 {
	status = "okay";
};

&mdss_dp0_out {
	/*
	 * Pin Assignment C/D/E: 2 DP lanes (multi-function with USB 3.x).
	 * Pin Assignment A/B: 4 DP lanes (DP-only mode, no USB 3.x SS).
	 * Use 2-lane config as default since SPX has USB 3.x functionality.
	 */
	data-lanes = <0 1>;
	remote-endpoint = <&usb_prim_qmpphy_dp_in>;
};

&mdss_dp1 {
	status = "okay";
};

&mdss_dp1_out {
	data-lanes = <0 1>;
	remote-endpoint = <&usb_sec_qmpphy_dp_in>;
};


&usb_prim_hsphy {
	status = "okay";
	vdda-pll-supply = <&vreg_l9e_0p88>;
	vdda18-supply = <&vreg_l12a_1p8>;
	vdda33-supply = <&vreg_l16e_3p1>;
};

&usb_prim_qmpphy {
	status = "okay";
	vdda-phy-supply = <&vreg_l3c_1p2>;
	vdda-pll-supply = <&vreg_l9e_0p88>;

	/* Required for USB-C orientation switching and DP Alt Mode */
	orientation-switch;
};

&usb_prim {
	status = "okay";
};

&usb_prim_dwc3 {
	/*
	 * USB-C port supports dual-role (host and device).
	 * Set to "otg" to allow role switching via pmic-glink UCSI.
	 * Windows uses UCSI over PMIC GLINK for role management.
	 */
	dr_mode = "otg";
	usb-role-switch;
};

&usb_prim_dwc3_hs {
	remote-endpoint = <&pmic_glink_con0_hs>;
};

&usb_prim_qmpphy_dp_in {
	remote-endpoint = <&mdss_dp0_out>;
};

&usb_prim_qmpphy_out {
	remote-endpoint = <&pmic_glink_con0_ss>;
};

&usb_sec_hsphy {
	status = "okay";
	vdda-pll-supply = <&vreg_l9e_0p88>;
	vdda18-supply = <&vreg_l12a_1p8>;
	vdda33-supply = <&vreg_l16e_3p1>;
};

&usb_sec_qmpphy {
	status = "okay";
	vdda-phy-supply = <&vreg_l3c_1p2>;
	vdda-pll-supply = <&vreg_l9e_0p88>;

	/* Required for USB-C orientation switching and DP Alt Mode */
	orientation-switch;
};

&usb_sec {
	status = "okay";
};

&usb_sec_dwc3 {
	/*
	 * Second USB-C port supports dual-role via UCSI.
	 * Set to "otg" to allow role switching via pmic-glink UCSI.
	 */
	dr_mode = "otg";
	usb-role-switch;
};

&usb_sec_dwc3_hs {
	remote-endpoint = <&pmic_glink_con1_hs>;
};

&usb_sec_qmpphy_dp_in {
	remote-endpoint = <&mdss_dp1_out>;
};

&usb_sec_qmpphy_out {
	remote-endpoint = <&pmic_glink_con1_ss>;
};

&usb_mp_hsphy0 {
	status = "okay";
	vdda-pll-supply = <&vreg_l9e_0p88>;
	vdda18-supply = <&vreg_l12a_1p8>;
	vdda33-supply = <&vreg_l16e_3p1>;
};

&usb_mp_hsphy1 {
	status = "okay";
	vdda-pll-supply = <&vreg_l9e_0p88>;
	vdda18-supply = <&vreg_l12a_1p8>;
	vdda33-supply = <&vreg_l16e_3p1>;
};

&usb_mp_qmpphy0 {
	status = "okay";
	vdda-phy-supply = <&vreg_l3c_1p2>;
	vdda-pll-supply = <&vreg_l9e_0p88>;
};

&usb_mp_qmpphy1 {
	status = "okay";
	vdda-phy-supply = <&vreg_l3c_1p2>;
	vdda-pll-supply = <&vreg_l9e_0p88>;
};

&usb_mp {
	status = "okay";
};

&usb_mp_dwc3 {
	dr_mode = "host";
};


// TODO:
// - PCIe has some sleep mode via a dedicated GPIO for all devices/ports
// - PCIe 3 has pin connections, but hot-plug commands time out.
//   pcieport 0003:00:00.0: pciehp: Timeout on hotplug command 0x03c0 (issued 3030 msec ago)
// - PCIe 1 and 2 work together? How do we express this here?
//   - apparently 2 phys can work with one controller (each providing 2 lanes)
//   - support for this is WIP (by Johan Hovold)
//   - right now, there seem to be two options:
//     - rely on UEFI to configure the second phy for us, which may cause problems with suspend
//     - use 2 lanes only, which _hopefully_ lets us avoid the second phy for now

&pcie2 {
	status = "okay";

	num-lanes = <2>;

	perst-gpio = <&tlmm 102 GPIO_ACTIVE_LOW>;
	wake-gpio = <&tlmm 104 GPIO_ACTIVE_HIGH>;
	pinctrl-names = "default";
	pinctrl-0 = <&pcie1_default_state>;

	// phys = <&pcie1_lane>, <&pcie1_lane>;
	// phy-names = "pciephy0", "pciephy1";

	// HACK: Remove "global" interrupt
	interrupts = <GIC_SPI 672 IRQ_TYPE_LEVEL_HIGH>,
		     <GIC_SPI 671 IRQ_TYPE_LEVEL_HIGH>,
		     <GIC_SPI 670 IRQ_TYPE_LEVEL_HIGH>,
		     <GIC_SPI 669 IRQ_TYPE_LEVEL_HIGH>,
		     <GIC_SPI 668 IRQ_TYPE_LEVEL_HIGH>,
		     <GIC_SPI 667 IRQ_TYPE_LEVEL_HIGH>,
		     <GIC_SPI 666 IRQ_TYPE_LEVEL_HIGH>,
		     <GIC_SPI 665 IRQ_TYPE_LEVEL_HIGH>;
	interrupt-names = "msi0",
			  "msi1",
			  "msi2",
			  "msi3",
			  "msi4",
			  "msi5",
			  "msi6",
			  "msi7";
};

// &pcie1_phy {
// 	status = "okay";
// 	vdda-phy-supply = <&vreg_l5e_0p88>;
// 	vdda-pll-supply = <&vreg_l3c_1p2>;
// };

&pcie2_phy {
	status = "okay";
	vdda-phy-supply = <&vreg_l5e_0p88>;
	vdda-pll-supply = <&vreg_l3c_1p2>;
};


&remoteproc_adsp {
	status = "okay";
	memory-region = <&adsp_mem>;
	firmware-name = "qcom/msft/surface/pro-x-sq2/qcadsp8180.mbn";
};

&remoteproc_cdsp {
	status = "okay";
	memory-region = <&cdsp_mem>;
	firmware-name = "qcom/msft/surface/pro-x-sq2/qccdsp8180.mbn";
};

&remoteproc_mpss {
	status = "okay";
	memory-region = <&mpss_mem>;
	firmware-name = "qcom/msft/surface/pro-x-sq2/qcmpss8180.mbn";
};

&remoteproc_slpi {
	status = "okay";
	memory-region = <&scss_mem>;
	firmware-name = "qcom/msft/surface/pro-x-sq2/qcslpi8180.mbn";
};

&venus {
	status = "okay";
	memory-region = <&venus_mem>;
	firmware-name = "qcom/msft/surface/pro-x-sq2/qcvss8180.mbn";
};


&qupv3_id_0 {
	status = "okay";
};

&i2c4 {
	/*
	 * Four MAX34417 quad-channel power accumulators (Maxim MAX34417).
	 *
	 * Identified by cross-referencing ACPI DSDT: four instances of
	 * "MSHW0012" on I2C5 (ACPI resource base 0x890000 = QUP0_SE4 =
	 * DTS &i2c4) at slave addresses 0x14, 0x16, 0x18 and 0x1A.
	 *
	 * Each MAX34417 measures up to four voltage/current channel pairs
	 * and accumulates power (V * I) in internal registers.  Windows
	 * reads the accumulators via SurfacePowerMeter.sys to implement
	 * the DPTF (Dynamic Platform and Thermal Framework) power budget.
	 *
	 * I2C4 (QUP0_SE4): GPIO51=SDA, GPIO52=SCL, 400 kHz Fast Mode.
	 * No interrupt lines; the driver polls the accumulator registers.
	 */
	status = "okay";
	clock-frequency = <400000>;

	pinctrl-names = "default";
	pinctrl-0 = <&i2c4_active>;

	power-meter@14 {
		compatible = "maxim,max34417";
		reg = <0x14>;
	};

	power-meter@16 {
		compatible = "maxim,max34417";
		reg = <0x16>;
	};

	power-meter@18 {
		compatible = "maxim,max34417";
		reg = <0x18>;
	};

	power-meter@1a {
		compatible = "maxim,max34417";
		reg = <0x1a>;
	};
};

&spi1 {
	status = "okay";

	pinctrl-names = "default";
	pinctrl-0 = <&spi1_active>;

	hid@0 {
		compatible = "hid-over-spi";

		reg = <0>;
		// spi-max-frequency = <25000000>;
		spi-max-frequency = <12500000>;

		interrupts-extended = <&tlmm 122 IRQ_TYPE_EDGE_FALLING>;

		pinctrl-names = "active", "sleep", "reset";
		pinctrl-0 = <&spi1_hid0_reset_deassert &spi1_hid0_int_bias>;
		pinctrl-1 = <&spi1_hid0_reset_assert &spi1_hid0_int_unbias>;
		pinctrl-2 = <&spi1_hid0_reset_assert &spi1_hid0_int_bias>;

		vdd-supply = <&vreg_ts_5p0>;

		hid-descr-addr = <1>;
	};
};

&i2c2 {
	status = "okay";
	clock-frequency = <400000>;

	pinctrl-names = "default";
	pinctrl-0 = <&i2c2_active>, <&i2c2_als_active>;

	color-sensor@39 {
		/*
		 * AMS TCS3430 4-channel XYZ+IR color/ALS sensor.
		 *
		 * Identified by RE analysis of SurfaceLightSensor.sys (internally
		 * named SurfaceColorSensor.sys, version 1.37.139.0). The chip ID
		 * register (0x92) returns 0xDC. The Windows driver uses:
		 *   - DMF_VirtualHidAmbientLightSensor for lux output
		 *   - DMF_VirtualHidAmbientColorSensor for XYZ chromaticity
		 *   - DMF_SpbTarget for I2C (SPB framework)
		 *   - UsingGoldenCalibration for factory cal compensation
		 *
		 * I2C2 (QUP2): GPIO126=SDA, GPIO127=SCL, 400kHz Fast Mode.
		 * Interrupt: GPIO24, active-low, level-triggered.
		 */
		compatible = "ams,tcs3430";
		reg = <0x39>;

		interrupts-extended = <&tlmm 24 IRQ_TYPE_LEVEL_LOW>;
	};
};


&qupv3_id_1 {
	status = "okay";
};

&i2c9 {
	status = "okay";
	clock-frequency = <100000>;

	pinctrl-names = "default";
	pinctrl-0 = <&i2c9_active>;

	/*
	 * TODO: Fingerprint sensor (MSHW0125 / Microsoft Surface fingerprint).
	 *
	 * DSDT cross-reference: Device "MSHW0125" (_HID) on I2C9 (QUP1_SE1,
	 * GPIO39=SDA, GPIO40=SCL, 100 kHz Standard Mode).
	 *
	 * DSDT _CRS resources:
	 *   I2CSerialBusV2: 0x3e (primary), 0x44, 0x66, 0x50 (secondary addrs)
	 *   GpioInt:  TLMM GPIO 166, edge-triggered, active-low  (interrupt)
	 *   GpioIo:   TLMM GPIO 5, output-only                   (reset)
	 *
	 * There is no upstream Linux driver for this proprietary fingerprint
	 * controller as of 2026-03.  A driver node cannot be added until a
	 * compatible binding is upstreamed.  The node is intentionally left
	 * absent to avoid binding an unrecognised compatible string.
	 *
	 * When a driver becomes available, add a node such as:
	 *   fingerprint@3e {
	 *       compatible = "microsoft,mshw0125";
	 *       reg = <0x3e>;
	 *       interrupts-extended = <&tlmm 166 IRQ_TYPE_EDGE_FALLING>;
	 *       reset-gpios = <&tlmm 5 GPIO_ACTIVE_LOW>;
	 *   };
	 */
};


&qupv3_id_2 {
	status = "okay";
};

/*
 * Camera sensors — MIPI-CSI to Qualcomm Spectra 390 ISP.
 *
 * Three camera sensors identified in the ACPI DSDT.  None have upstream
 * Device Tree nodes yet; CAMSS / IFE support for SC8180X is a work in
 * progress.  Documented here for future driver enablement.
 *
 * 1. OV13858 — 13 MP rear RGB camera
 *    DSDT: Device "OVTI13B8" (_HID), I2C address 0x10
 *    MIPI: 4-lane MIPI-CSI2 @ 1.2 Gbps/lane (4800 Mbps aggregate)
 *    Clock: MCLK0 (gpio144), 24 MHz from camcc
 *    Controls: reset GPIO 78 (active-low), VANA/VDIG/VIO via RPMh
 *
 * 2. OV5693 — 5 MP front RGB camera
 *    DSDT: Device "OVTI5693" (_HID), I2C address 0x36
 *    MIPI: 2-lane MIPI-CSI2 @ 1.2 Gbps/lane
 *    Clock: MCLK1 (gpio145), 24 MHz from camcc
 *    Controls: reset GPIO 87 (active-low)
 *
 * 3. OV7251 — IR depth / Windows Hello camera
 *    DSDT: Device "OVTI7251" (_HID), I2C address 0x60
 *    MIPI: 1-lane MIPI-CSI2 @ 800 Mbps/lane
 *    Clock: MCLK2 (gpio146), 24 MHz from camcc
 *    Controls: reset GPIO 88 (active-low)
 *
 * All three sensors share an I2C bus on QUP2_SE0 (i2c16 in sc8180x.dtsi)
 * via GPIO140 (SDA) / GPIO141 (SCL).  Windows uses CameraSensor*.sys
 * (WDM kernel-mode driver stack via AvsCam.sys / QcomCamera.sys).
 *
 * TODO: Add CAMSS node for SC8180X IFE/VFE, then add sensor sub-nodes
 * with port/endpoint graphs tied to the appropriate CSI PHY.
 */

&uart13 {
	status = "okay";

	pinctrl-names = "default";
	pinctrl-0 = <&uart13_state>;

	bluetooth {
		// Note: The WCN3998 on Surface Pro X reports ROM version 0x01
		//       but the actual firmware files use version 0x21 (e.g.,
		//       crbtfw21.tlv and crnv21.bin extracted from Windows).
		//       We override the firmware file names here using the
		//       firmware-name DT property to avoid the mismatch.
		//       firmware-name[0] = NVM config, firmware-name[1] = rampatch.

		compatible = "qcom,wcn3998-bt";

		vddio-supply = <&vreg_s4a_1p8>;
		vddxo-supply = <&vreg_l7a_1p8>;
		vddrf-supply = <&vreg_l9a_1p3>;
		vddch0-supply = <&vreg_l11c_3p3>;

		max-speed = <3200000>;

		firmware-name = "crnv21.bin", "crbtfw21.tlv";
	};
};

&uart15 {
	status = "okay";

	pinctrl-names = "default";
	pinctrl-0 = <&uart15_state>;

	embedded-controller {
		compatible = "microsoft,surface-sam";

		interrupts-extended = <&tlmm 180 IRQ_TYPE_EDGE_RISING>;
		// Note: 133 is used in ACPI as an alternative for some boards.

		pinctrl-0 = <&ssam_state>;
		pinctrl-names = "default";

		current-speed = <4000000>;
	};
};

&wifi {
	status = "okay";

	memory-region = <&wlan_mem>;

	qcom,snoc-host-cap-skip-quirk;

	vdd-0.8-cx-mx-supply = <&vreg_l1e_0p75>;
	vdd-1.8-xo-supply = <&vreg_l7a_1p8>;
	vdd-1.3-rfa-supply = <&vreg_l9a_1p3>;
	vdd-3.3-ch0-supply = <&vreg_l11c_3p3>;
	vdd-3.3-ch1-supply = <&vreg_l10c_3p3>;
};

&ufs_mem_hc {
	status = "okay";

	/*
	 * UFS device reset GPIO. GPIO 190 is confirmed on both Flex 5G and
	 * Primus (the only two other sc8180x boards in mainline). Consistent
	 * with SC8180X platform design; verify against SPX board schematics.
	 */
	reset-gpios = <&tlmm 190 GPIO_ACTIVE_LOW>;

	/*
	 * VCC: UFS NAND array supply, 2.904 V (PMC8180-E LDO10).
	 * Both Flex 5G and Primus use vreg_l10e_2p9 at 155 mA max.
	 * Previous value (vreg_l16e_3p1 / 3.072 V) was incorrect --
	 * LDO16 is the USB vdda33 supply, not for UFS.
	 */
	vcc-supply = <&vreg_l10e_2p9>;
	vcc-max-microamp = <155000>;

	/*
	 * VCCQ2: UFS I/O supply, 1.8 V (PMC8180-E LDO7).
	 * Both Flex 5G and Primus use vreg_l7e_1p8 at 425 mA max.
	 * Previous value (vreg_s4a_1p8 / fixed SMPS) prevented load
	 * scaling needed for UFS power management transitions.
	 */
	vccq2-supply = <&vreg_l7e_1p8>;
	vccq2-max-microamp = <425000>;
};

&ufs_mem_phy {
	status = "okay";

	vdda-phy-supply = <&vreg_l5e_0p88>;
	vdda-pll-supply = <&vreg_l3c_1p2>;
};


/*
 * Audio subsystem: WCD9380 codec + LPASS macros + SoundWire buses
 *
 * The Surface Pro X uses a Qualcomm WCD9380 (WCD938x family) audio codec
 * connected over two SoundWire buses (RX on swr1, TX on swr2).  Speakers
 * are driven via the WSA SoundWire bus (swr0).  The LPASS macros (VA, RX,
 * TX, WSA) are instantiated in the ADSP address space and clocked through
 * the Q6AFE clock controller (q6afecc).
 *
 * The machine driver used is qcom,sm8250-sndcard (sm8250.c), which handles
 * the older APR/Q6AFE transport used by SC8180X (as opposed to the APM
 * transport used by SC8280XP).
 *
 * TODO items that require physical hardware verification:
 *   - WCD9380 reset GPIO number (search ACPI DSDT for QCOM0425 _CRS)
 *   - Speaker model (WSA8810/WSA8830) and SoundWire device addresses
 *   - DMIC pin assignments for built-in microphones (GPIO numbers)
 *   - Exact micbias voltages
 *
 * Reference: sm8250-mtp.dts (same APR/Q6AFE audio stack)
 */

/*
 * WCD9380 codec top-level node.
 *
 * The WCD9380 is a SoundWire multi-function device; the top-level
 * "qcom,wcd9380-codec" node ties together the RX and TX SoundWire
 * slave devices enumerated on swr1 and swr2 respectively.
 *
 * Supply names are taken directly from wcd938x.c:
 *   static const char * const wcd938x_supplies[] = {
 *       "vdd-rxtx", "vdd-io", "vdd-buck", "vdd-mic-bias",
 *   };
 *
 * vreg_s4a_1p8 (1.8 V) is used for vdd-buck, vdd-rxtx, and vdd-io.
 * vreg_bob (3.3 V) is used for vdd-mic-bias (headset mic bias).
 *
 * TODO: reset-gpios — GPIO number needs ACPI DSDT verification.
 *       On SM8250-MTP this is GPIO 32; on ThinkPad X13s it is GPIO 106.
 *       Until confirmed, leave commented out to avoid a hard fault at
 *       probe time.
 */
&sound {
	compatible = "qcom,sm8250-sndcard";
	model = "SC8180X-SURFACE-PRO-X";

	audio-routing =
		"SpkrLeft IN", "WSA_SPK1 OUT",
		"SpkrRight IN", "WSA_SPK2 OUT",
		"IN1_HPHL", "HPHL_OUT",
		"IN2_HPHR", "HPHR_OUT",
		"AMIC2", "MIC BIAS2",
		"TX SWR_ADC1", "ADC2_OUTPUT";

	mm1-dai-link {
		link-name = "MultiMedia1";
		cpu {
			sound-dai = <&q6asmdai MSM_FRONTEND_DAI_MULTIMEDIA1>;
		};
	};

	mm2-dai-link {
		link-name = "MultiMedia2";
		cpu {
			sound-dai = <&q6asmdai MSM_FRONTEND_DAI_MULTIMEDIA2>;
		};
	};

	mm3-dai-link {
		link-name = "MultiMedia3";
		cpu {
			sound-dai = <&q6asmdai MSM_FRONTEND_DAI_MULTIMEDIA3>;
		};
	};

	wcd-playback-dai-link {
		link-name = "WCD Playback";
		cpu {
			sound-dai = <&q6afedai RX_CODEC_DMA_RX_0>;
		};

		codec {
			sound-dai = <&wcd938x 0>, <&swr1 0>, <&rxmacro 0>;
		};

		platform {
			sound-dai = <&q6routing>;
		};
	};

	wcd-capture-dai-link {
		link-name = "WCD Capture";
		cpu {
			sound-dai = <&q6afedai TX_CODEC_DMA_TX_3>;
		};

		codec {
			sound-dai = <&wcd938x 1>, <&swr2 0>, <&txmacro 0>;
		};

		platform {
			sound-dai = <&q6routing>;
		};
	};

	wsa-dai-link {
		link-name = "WSA Playback";
		cpu {
			sound-dai = <&q6afedai WSA_CODEC_DMA_RX_0>;
		};

		codec {
			sound-dai = <&left_spkr>, <&right_spkr>,
				    <&swr0 0>, <&wsamacro 0>;
		};

		platform {
			sound-dai = <&q6routing>;
		};
	};

	va-dai-link {
		link-name = "VA Capture";
		cpu {
			sound-dai = <&q6afedai VA_CODEC_DMA_TX_0>;
		};

		platform {
			sound-dai = <&q6routing>;
		};

		codec {
			sound-dai = <&vamacro 0>;
		};
	};
};

/*
 * WSA SoundWire bus — speaker amplifiers.
 *
 * DSDT confirms WSA8810 at SDW addresses 0x3 (left) and 0x4 (right).
 * Compatible string sdw20217020100 matches the upstream wsa881x driver
 * (sound/soc/codecs/wsa881x.c) and the DSDT _ADR encoding.
 *
 * There is NO powerdown GPIO: WSA power sequencing is managed by the
 * ADSP firmware over the SoundWire control port.  The DSDT _CRS for
 * both WSA8810 devices contains no GpioIo resource.
 */
&swr0 {
	status = "okay";

	left_spkr: speaker@0,3 {
		compatible = "sdw20217020100";
		reg = <0 3>;
		/* WSA power is managed by ADSP firmware over SoundWire — no GPIO needed. */
		#thermal-sensor-cells = <0>;
		sound-name-prefix = "SpkrLeft";
		#sound-dai-cells = <0>;
	};

	right_spkr: speaker@0,4 {
		compatible = "sdw20217020100";
		reg = <0 4>;
		/* WSA power is managed by ADSP firmware over SoundWire — no GPIO needed. */
		#thermal-sensor-cells = <0>;
		sound-name-prefix = "SpkrRight";
		#sound-dai-cells = <0>;
	};
};

/*
 * RX SoundWire bus — WCD9380 playback (headphone, earpiece).
 *
 * The WCD9380 RX slave is always at SoundWire address (link=0, dev=4).
 * qcom,rx-port-mapping matches the five RX ports on WCD938x.
 */
&swr1 {
	status = "okay";

	wcd_rx: wcd9380-rx@0,4 {
		compatible = "sdw20217010d00";
		reg = <0 4>;
		qcom,rx-port-mapping = <1 2 3 4 5>;
	};
};

/*
 * TX SoundWire bus — WCD9380 capture (microphone).
 *
 * The WCD9380 TX slave is always at SoundWire address (link=0, dev=3).
 * qcom,tx-port-mapping matches the four TX ports on WCD938x.
 */
&swr2 {
	status = "okay";

	wcd_tx: wcd9380-tx@0,3 {
		compatible = "sdw20217010d00";
		reg = <0 3>;
		qcom,tx-port-mapping = <2 3 4 5>;
	};
};

/*
 * LPASS macro enables.
 *
 * All four LPASS codec macros (VA, RX, TX, WSA) must be enabled for
 * the audio stack to function.  They are clocked through q6afecc and
 * are defined as disabled in sc8180x.dtsi.
 *
 * vamacro: VA macro — digital microphone (DMIC) capture path.
 *   TODO: add dmic01/dmic23 pinctrl states once GPIO assignments are
 *   confirmed via ACPI DSDT analysis.
 */
&vamacro {
	status = "okay";
};

&rxmacro {
	status = "okay";
};

&txmacro {
	status = "okay";
};

&wsamacro {
	status = "okay";
};

/*
 * WCD9380 top-level codec node.
 *
 * Binds the RX slave (wcd_rx / swr1) and TX slave (wcd_tx / swr2).
 * Supply names match wcd938x.c; vreg_s4a_1p8 is the 1.8 V always-on
 * rail and vreg_bob provides 3.3 V for mic-bias.
 * reset-gpios confirmed as TLMM GPIO 143 via DSDT QCOM0425 _CRS.
 */
/ {
	wcd938x: audio-codec {
		compatible = "qcom,wcd9380-codec";

		reset-gpios = <&tlmm 143 GPIO_ACTIVE_LOW>;
		pinctrl-names = "default";
		pinctrl-0 = <&wcd938x_reset_default>;

		vdd-buck-supply = <&vreg_s4a_1p8>;
		vdd-rxtx-supply = <&vreg_s4a_1p8>;
		vdd-io-supply = <&vreg_s4a_1p8>;
		vdd-mic-bias-supply = <&vreg_bob>;

		qcom,micbias1-microvolt = <1800000>;
		qcom,micbias2-microvolt = <1800000>;
		qcom,micbias3-microvolt = <1800000>;
		qcom,micbias4-microvolt = <1800000>;

		qcom,mbhc-buttons-vthreshold-microvolt = <75000 150000 237000 500000
							   500000 500000 500000 500000>;
		qcom,mbhc-headset-vthreshold-microvolt = <1700000>;
		qcom,mbhc-headphone-vthreshold-microvolt = <50000>;

		qcom,rx-device = <&wcd_rx>;
		qcom,tx-device = <&wcd_tx>;

		#sound-dai-cells = <1>;
	};
};


/*
 * PMIC ADC-TM5 (threshold monitor) -- pmc8180a (USID 0x0)
 *
 * Enable the ADC threshold monitor and register the two NTC thermistor
 * channels defined above in pmc8180a_adc.  Each child node's reg value
 * is the sequential index used by the #thermal-sensor-cells = <1>
 * binding (referenced from thermal-zones above as <&pmc8180_adc_tm N>).
 *
 * io-channels points back into the ADC so the TM driver can read the
 * current raw ADC value for threshold comparisons.
 */
&pmc8180_adc_tm {
	status = "okay";

	sys-therm1@0 {
		reg = <0>;
		io-channels = <&pmc8180a_adc ADC5_AMUX_THM1_100K_PU>;
		qcom,ratiometric;
		qcom,hw-settle-time-us = <200>;
	};

	pa-therm@1 {
		reg = <1>;
		io-channels = <&pmc8180a_adc ADC5_AMUX_THM2_100K_PU>;
		qcom,ratiometric;
		qcom,hw-settle-time-us = <200>;
	};
};

/*
 * PMIC ADC-TM5 (threshold monitor) -- pmc8180c (USID 0x4)
 *
 * Three NTC thermistor channels on the pmc8180c PMIC.  reg values 0-2
 * correspond to the three channel sub-nodes (sys_therm2, sys_therm3,
 * pa_therm1) in pmc8180c_adc above.
 */
&pmc8180c_adc_tm {
	status = "okay";

	sys-therm2@0 {
		reg = <0>;
		io-channels = <&pmc8180c_adc ADC5_AMUX_THM1_100K_PU>;
		qcom,ratiometric;
		qcom,hw-settle-time-us = <200>;
	};

	sys-therm3@1 {
		reg = <1>;
		io-channels = <&pmc8180c_adc ADC5_AMUX_THM2_100K_PU>;
		qcom,ratiometric;
		qcom,hw-settle-time-us = <200>;
	};

	pa-therm1@2 {
		reg = <2>;
		io-channels = <&pmc8180c_adc ADC5_AMUX_THM3_100K_PU>;
		qcom,ratiometric;
		qcom,hw-settle-time-us = <200>;
	};
};
